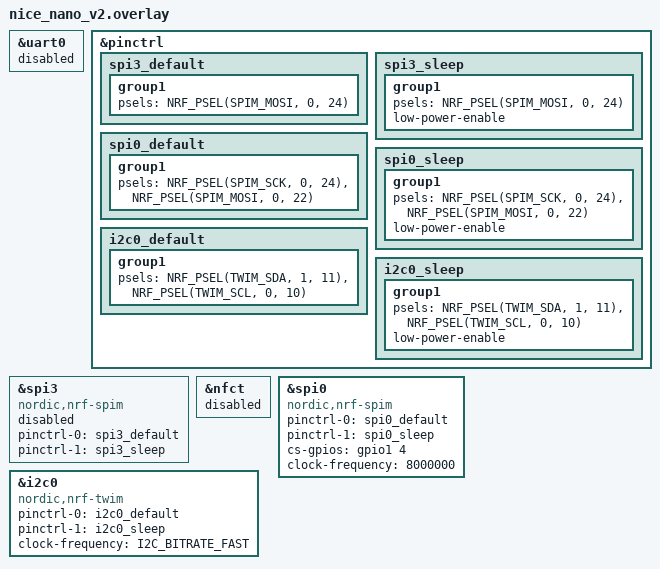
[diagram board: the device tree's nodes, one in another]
&uart0 {
    status = "disabled";
};
&pinctrl {
    spi3_default: spi3_default {
        group1 {
            psels = <NRF_PSEL(SPIM_MOSI, 0, 24)>;
        };
    };
    spi3_sleep: spi3_sleep {
        group1 {
            psels = <NRF_PSEL(SPIM_MOSI, 0, 24)>;
            low-power-enable;
        };
    };
    spi0_default: spi0_default {
        group1 {
            psels = <NRF_PSEL(SPIM_SCK, 0, 24)>,
                    <NRF_PSEL(SPIM_MOSI, 0, 22)>;
        };
    };
    spi0_sleep: spi0_sleep {
        group1 {
            psels = <NRF_PSEL(SPIM_SCK, 0, 24)>,
                    <NRF_PSEL(SPIM_MOSI, 0, 22)>;
            low-power-enable;
        };
    };
    i2c0_default: i2c0_default {
        group1 {
            psels = <NRF_PSEL(TWIM_SDA, 1, 11)>,
                    <NRF_PSEL(TWIM_SCL, 0, 10)>;
        };
    };
    i2c0_sleep: i2c0_sleep {
        group1 {
            psels = <NRF_PSEL(TWIM_SDA, 1, 11)>,
                    <NRF_PSEL(TWIM_SCL, 0, 10)>;
            low-power-enable;
        };
    };
};
&spi3 {
    compatible = "nordic,nrf-spim";
    status = "disabled";
    pinctrl-0 = <&spi3_default>;
    pinctrl-1 = <&spi3_sleep>;
    pinctrl-names = "default", "sleep";
};
&nfct {
    status = "disabled";
};
nice_view_spi: &spi0 {
    compatible = "nordic,nrf-spim";
    status = "okay";
    pinctrl-0 = <&spi0_default>;
    pinctrl-1 = <&spi0_sleep>;
    pinctrl-names = "default", "sleep";
    cs-gpios = <&gpio1 4 GPIO_ACTIVE_HIGH>;
    clock-frequency = <8000000>;
};
&i2c0 {
    compatible = "nordic,nrf-twim";
    pinctrl-0 = <&i2c0_default>;
    pinctrl-1 = <&i2c0_sleep>;
    pinctrl-names = "default", "sleep";
    clock-frequency = <I2C_BITRATE_FAST>;
};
